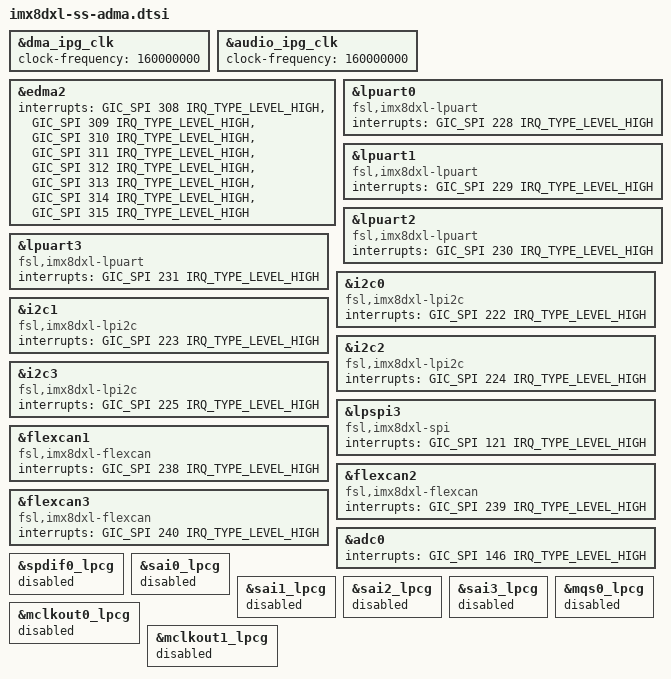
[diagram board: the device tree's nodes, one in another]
// SPDX-License-Identifier: GPL-2.0+
/*
 * Copyright 2019~2020 NXP
 */

&dma_ipg_clk {
	clock-frequency = <160000000>;
};

&audio_ipg_clk {
	clock-frequency = <160000000>;
};

&edma2 {
	interrupts = <GIC_SPI 308 IRQ_TYPE_LEVEL_HIGH>,
		     <GIC_SPI 309 IRQ_TYPE_LEVEL_HIGH>,
		     <GIC_SPI 310 IRQ_TYPE_LEVEL_HIGH>,
		     <GIC_SPI 311 IRQ_TYPE_LEVEL_HIGH>,
		     <GIC_SPI 312 IRQ_TYPE_LEVEL_HIGH>,
		     <GIC_SPI 313 IRQ_TYPE_LEVEL_HIGH>,
		     <GIC_SPI 314 IRQ_TYPE_LEVEL_HIGH>,
		     <GIC_SPI 315 IRQ_TYPE_LEVEL_HIGH>;
};

&lpuart0 {
	compatible = "fsl,imx8dxl-lpuart", "fsl,imx8qxp-lpuart", "fsl,imx7ulp-lpuart";
	interrupts = <GIC_SPI 228 IRQ_TYPE_LEVEL_HIGH>;
};

&lpuart1 {
	compatible = "fsl,imx8dxl-lpuart", "fsl,imx8qxp-lpuart", "fsl,imx7ulp-lpuart";
	interrupts = <GIC_SPI 229 IRQ_TYPE_LEVEL_HIGH>;
};

&lpuart2 {
	compatible = "fsl,imx8dxl-lpuart", "fsl,imx8qxp-lpuart", "fsl,imx7ulp-lpuart";
	interrupts = <GIC_SPI 230 IRQ_TYPE_LEVEL_HIGH>;
};

&lpuart3 {
	compatible = "fsl,imx8dxl-lpuart", "fsl,imx8qxp-lpuart", "fsl,imx7ulp-lpuart";
	interrupts = <GIC_SPI 231 IRQ_TYPE_LEVEL_HIGH>;
};

&i2c0 {
	compatible = "fsl,imx8dxl-lpi2c", "fsl,imx8qxp-lpi2c", "fsl,imx7ulp-lpi2c";
	interrupts = <GIC_SPI 222 IRQ_TYPE_LEVEL_HIGH>;
};

&i2c1 {
	compatible = "fsl,imx8dxl-lpi2c", "fsl,imx8qxp-lpi2c", "fsl,imx7ulp-lpi2c";
	interrupts = <GIC_SPI 223 IRQ_TYPE_LEVEL_HIGH>;
};

&i2c2 {
	compatible = "fsl,imx8dxl-lpi2c", "fsl,imx8qxp-lpi2c", "fsl,imx7ulp-lpi2c";
	interrupts = <GIC_SPI 224 IRQ_TYPE_LEVEL_HIGH>;
};

&i2c3 {
	compatible = "fsl,imx8dxl-lpi2c", "fsl,imx8qxp-lpi2c", "fsl,imx7ulp-lpi2c";
	interrupts = <GIC_SPI 225 IRQ_TYPE_LEVEL_HIGH>;
};

&lpspi3 {
	compatible = "fsl,imx8dxl-spi", "fsl,imx8qxp-spi", "fsl,imx7ulp-spi";
	interrupts = <GIC_SPI 121 IRQ_TYPE_LEVEL_HIGH>;
};

&flexcan1 {
	compatible = "fsl,imx8dxl-flexcan", "fsl,imx8qxp-flexcan", "fsl,imx8qm-flexcan";
	interrupts = <GIC_SPI 238 IRQ_TYPE_LEVEL_HIGH>;
};

&flexcan2 {
	compatible = "fsl,imx8dxl-flexcan", "fsl,imx8qxp-flexcan", "fsl,imx8qm-flexcan";
	interrupts = <GIC_SPI 239 IRQ_TYPE_LEVEL_HIGH>;
};

&flexcan3 {
	compatible = "fsl,imx8dxl-flexcan", "fsl,imx8qxp-flexcan", "fsl,imx8qm-flexcan";
	interrupts = <GIC_SPI 240 IRQ_TYPE_LEVEL_HIGH>;
};

&adc0 {
	interrupts = <GIC_SPI 146 IRQ_TYPE_LEVEL_HIGH>;
};

&spdif0_lpcg {
	status = "disabled";
};

&sai0_lpcg {
	status = "disabled";
};

&sai1_lpcg {
	status = "disabled";
};

&sai2_lpcg {
	status = "disabled";
};

&sai3_lpcg {
	status = "disabled";
};

&mqs0_lpcg {
	status = "disabled";
};

&mclkout0_lpcg {
	status = "disabled";
};

&mclkout1_lpcg {
	status = "disabled";
};
